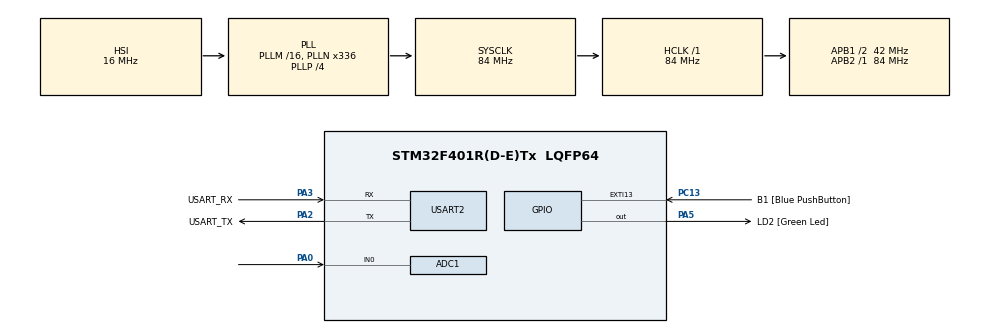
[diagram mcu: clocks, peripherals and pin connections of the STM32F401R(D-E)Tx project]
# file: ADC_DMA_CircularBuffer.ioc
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Mcu.Family=STM32F4
PC15-OSC32_OUT.Mode=LSE-External-Oscillator
PA2.GPIO_PuPd=GPIO_NOPULL
Dma.ADC1.0.Instance=DMA2_Stream0
RCC.CortexFreq_Value=84000000
ADC1.Rank-0\#ChannelRegularConversion=1
PC13-ANTI_TAMP.GPIO_PuPd=GPIO_NOPULL
ADC1.ContinuousConvMode=ENABLE
PC13-ANTI_TAMP.GPIO_Label=B1 [Blue PushButton]
PA14.GPIO_Label=TCK
PA3.GPIO_PuPd=GPIO_NOPULL
PH1\ -\ OSC_OUT.Mode=HSE-External-Clock-Source
PA2.GPIO_Speed=GPIO_SPEED_FREQ_LOW
RCC.APB1CLKDivider=RCC_HCLK_DIV2
PC14-OSC32_IN.Signal=RCC_OSC32_IN
PA3.GPIO_Speed=GPIO_SPEED_FREQ_LOW
RCC.SYSCLKSource=RCC_SYSCLKSOURCE_PLLCLK
ProjectManager.StackSize=0x400
PA0-WKUP.Signal=ADCx_IN0
PA3.Mode=Asynchronous
PA13.Signal=SYS_JTMS-SWDIO
Dma.ADC1.0.PeriphDataAlignment=DMA_PDATAALIGN_HALFWORD
PH0\ -\ OSC_IN.Mode=HSE-External-Clock-Source
PH0\ -\ OSC_IN.Signal=RCC_OSC_IN
ProjectManager.TargetToolchain=Other Toolchains (GPDSC)
Dma.ADC1.0.Mode=DMA_CIRCULAR
PA3.GPIO_Mode=GPIO_MODE_AF_PP
RCC.HCLKFreq_Value=84000000
Dma.ADC1.0.Priority=DMA_PRIORITY_LOW
RCC.APB2TimFreq_Value=84000000
Dma.ADC1.0.Direction=DMA_PERIPH_TO_MEMORY
NVIC.DMA2_Stream0_IRQn=true\:0\:0\:false\:false\:true\:false\:true
PC15-OSC32_OUT.Signal=RCC_OSC32_OUT
Dma.ADC1.0.MemDataAlignment=DMA_MDATAALIGN_HALFWORD
RCC.AHBFreq_Value=84000000
PA5.Signal=GPIO_Output
ADC1.Channel-0\#ChannelRegularConversion=ADC_CHANNEL_0
RCC.HSE_VALUE=8000000
PH1\ -\ OSC_OUT.Signal=RCC_OSC_OUT
board=NUCLEO-F401RE
PC13-ANTI_TAMP.Signal=GPXTI13
RCC.VCOOutputFreq_Value=336000000
RCC.APB2Freq_Value=84000000
PC14-OSC32_IN.Mode=LSE-External-Oscillator
PA14.Mode=Serial_Wire
PA5.GPIO_PuPd=GPIO_NOPULL
Dma.ADC1.0.PeriphInc=DMA_PINC_DISABLE
SH.ADCx_IN0.0=ADC1_IN0,IN0
ADC1.DMAContinuousRequests=ENABLE
PA13.Mode=Serial_Wire
Mcu.Name=STM32F401R(D-E)Tx
ADC1.SamplingTime-0\#ChannelRegularConversion=ADC_SAMPLETIME_3CYCLES
PA2.Signal=USART2_TX
PA13.GPIO_Label=TMS
RCC.48MHZClocksFreq_Value=48000000
PB3.Signal=SYS_JTDO-SWO
RCC.SYSCLKFreq_VALUE=84000000
Mcu.Package=LQFP64
ADC1.master=1
PA5.GPIO_Label=LD2 [Green Led]
USART2.VirtualMode=VM_ASYNC
PC13-ANTI_TAMP.GPIO_ModeDefaultEXTI=GPIO_MODE_IT_FALLING
PA2.GPIO_Label=USART_TX
PA14.Signal=SYS_JTCK-SWCLK
Dma.ADC1.0.MemInc=DMA_MINC_ENABLE
ProjectManager.HeapSize=0x200
RCC.HSI_VALUE=16000000
RCC.PLLP=RCC_PLLP_DIV4
PA5.GPIO_Speed=GPIO_SPEED_FREQ_LOW
RCC.PLLQ=7
NVIC.PriorityGroup=NVIC_PRIORITYGROUP_0
ADC1.NbrOfConversionFlag=1
RCC.PLLN=336
RCC.APB1TimFreq_Value=84000000
PA2.Mode=Asynchronous
Dma.ADC1.0.FIFOMode=DMA_FIFOMODE_DISABLE
Dma.Request0=ADC1
RCC.APB1Freq_Value=42000000
PA5.GPIO_Mode=GPIO_MODE_OUTPUT_PP
PA3.GPIO_Label=USART_RX
PA3.Signal=USART2_RX
PA2.GPIO_Mode=GPIO_MODE_AF_PP
PB3.GPIO_Label=SWO

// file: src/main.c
/* USER CODE BEGIN Header */
/**
  ******************************************************************************
  * @file           : main.c
  * @brief          : Main program body
  ******************************************************************************
  * @attention
  *
  * <h2><center>&copy; Copyright (c) 2021 STMicroelectronics.
  * All rights reserved.</center></h2>
  *
  * This software component is licensed by ST under BSD 3-Clause license,
  * the "License"; You may not use this file except in compliance with the
  * License. You may obtain a copy of the License at:
  *                        opensource.org/licenses/BSD-3-Clause
  *
  ******************************************************************************
  */
/* USER CODE END Header */
#include "main.h"

ADC_HandleTypeDef hadc1;
DMA_HandleTypeDef hdma_adc1;

UART_HandleTypeDef huart2;

/* USER CODE BEGIN PV */
uint16_t adc_data[16];
/* USER CODE END PV */

void SystemClock_Config(void);
static void MX_GPIO_Init(void);
static void MX_DMA_Init(void);
static void MX_ADC1_Init(void);
static void MX_USART2_UART_Init(void);

/* USER CODE BEGIN 0 */
void HAL_ADC_ConvCpltCallback(ADC_HandleTypeDef* hadc)
{
  __NOP();
}
/* USER CODE END 0 */

int main(void)
{

  /* MCU Configuration--------------------------------------------------------*/

  /* Reset of all peripherals, Initializes the Flash interface and the Systick. */
  HAL_Init();

  /* Configure the system clock */
  SystemClock_Config();

  /* Initialize all configured peripherals */
  MX_GPIO_Init();
  MX_DMA_Init();
  MX_ADC1_Init();
  MX_USART2_UART_Init();

  /* USER CODE BEGIN 2 */
  HAL_ADC_Start_DMA(&hadc1, (uint32_t*)adc_data, 16);
  /* USER CODE END 2 */

  /* Infinite loop */
  while (1)
  {

  }
}

void SystemClock_Config(void)
{
  RCC_OscInitTypeDef RCC_OscInitStruct = {0};
  RCC_ClkInitTypeDef RCC_ClkInitStruct = {0};

  /** Configure the main internal regulator output voltage
  */
  __HAL_RCC_PWR_CLK_ENABLE();
  __HAL_PWR_VOLTAGESCALING_CONFIG(PWR_REGULATOR_VOLTAGE_SCALE2);
  /** Initializes the RCC Oscillators according to the specified parameters
  * in the RCC_OscInitTypeDef structure.
  */
  RCC_OscInitStruct.OscillatorType = RCC_OSCILLATORTYPE_HSI;
  RCC_OscInitStruct.HSIState = RCC_HSI_ON;
  RCC_OscInitStruct.HSICalibrationValue = RCC_HSICALIBRATION_DEFAULT;
  RCC_OscInitStruct.PLL.PLLState = RCC_PLL_ON;
  RCC_OscInitStruct.PLL.PLLSource = RCC_PLLSOURCE_HSI;
  RCC_OscInitStruct.PLL.PLLM = 16;
  RCC_OscInitStruct.PLL.PLLN = 336;
  RCC_OscInitStruct.PLL.PLLP = RCC_PLLP_DIV4;
  RCC_OscInitStruct.PLL.PLLQ = 7;
  if (HAL_RCC_OscConfig(&RCC_OscInitStruct) != HAL_OK)
  {
    Error_Handler();
  }
  /** Initializes the CPU, AHB and APB buses clocks
  */
  RCC_ClkInitStruct.ClockType = RCC_CLOCKTYPE_HCLK|RCC_CLOCKTYPE_SYSCLK
                              |RCC_CLOCKTYPE_PCLK1|RCC_CLOCKTYPE_PCLK2;
  RCC_ClkInitStruct.SYSCLKSource = RCC_SYSCLKSOURCE_PLLCLK;
  RCC_ClkInitStruct.AHBCLKDivider = RCC_SYSCLK_DIV1;
  RCC_ClkInitStruct.APB1CLKDivider = RCC_HCLK_DIV2;
  RCC_ClkInitStruct.APB2CLKDivider = RCC_HCLK_DIV1;

  if (HAL_RCC_ClockConfig(&RCC_ClkInitStruct, FLASH_LATENCY_2) != HAL_OK)
  {
    Error_Handler();
  }
}

static void MX_ADC1_Init(void)
{

  ADC_ChannelConfTypeDef sConfig = {0};

  /** Configure the global features of the ADC (Clock, Resolution, Data Alignment and number of conversion)
  */
  hadc1.Instance = ADC1;
  hadc1.Init.ClockPrescaler = ADC_CLOCK_SYNC_PCLK_DIV4;
  hadc1.Init.Resolution = ADC_RESOLUTION_12B;
  hadc1.Init.ScanConvMode = DISABLE;
  hadc1.Init.ContinuousConvMode = ENABLE;
  hadc1.Init.DiscontinuousConvMode = DISABLE;
  hadc1.Init.ExternalTrigConvEdge = ADC_EXTERNALTRIGCONVEDGE_NONE;
  hadc1.Init.ExternalTrigConv = ADC_SOFTWARE_START;
  hadc1.Init.DataAlign = ADC_DATAALIGN_RIGHT;
  hadc1.Init.NbrOfConversion = 1;
  hadc1.Init.DMAContinuousRequests = ENABLE;
  hadc1.Init.EOCSelection = ADC_EOC_SINGLE_CONV;

  if (HAL_ADC_Init(&hadc1) != HAL_OK)
  {
    Error_Handler();
  }
  /** Configure for the selected ADC regular channel its corresponding rank in the sequencer and its sample time.
  */
  sConfig.Channel = ADC_CHANNEL_0;
  sConfig.Rank = 1;
  sConfig.SamplingTime = ADC_SAMPLETIME_3CYCLES;
  if (HAL_ADC_ConfigChannel(&hadc1, &sConfig) != HAL_OK)
  {
    Error_Handler();
  }

}

static void MX_USART2_UART_Init(void)
{

  huart2.Instance = USART2;
  huart2.Init.BaudRate = 115200;
  huart2.Init.WordLength = UART_WORDLENGTH_8B;
  huart2.Init.StopBits = UART_STOPBITS_1;
  huart2.Init.Parity = UART_PARITY_NONE;
  huart2.Init.Mode = UART_MODE_TX_RX;
  huart2.Init.HwFlowCtl = UART_HWCONTROL_NONE;
  huart2.Init.OverSampling = UART_OVERSAMPLING_16;
  if (HAL_UART_Init(&huart2) != HAL_OK)
  {
    Error_Handler();
  }

}

static void MX_DMA_Init(void)
{

  /* DMA controller clock enable */
  __HAL_RCC_DMA2_CLK_ENABLE();

  /* DMA interrupt init */
  /* DMA2_Stream0_IRQn interrupt configuration */
  HAL_NVIC_SetPriority(DMA2_Stream0_IRQn, 0, 0);
  HAL_NVIC_EnableIRQ(DMA2_Stream0_IRQn);

}

static void MX_GPIO_Init(void)
{
  GPIO_InitTypeDef GPIO_InitStruct = {0};

  /* GPIO Ports Clock Enable */
  __HAL_RCC_GPIOC_CLK_ENABLE();
  __HAL_RCC_GPIOH_CLK_ENABLE();
  __HAL_RCC_GPIOA_CLK_ENABLE();
  __HAL_RCC_GPIOB_CLK_ENABLE();

  /*Configure GPIO pin Output Level */
  HAL_GPIO_WritePin(LD2_GPIO_Port, LD2_Pin, GPIO_PIN_RESET);

  /*Configure GPIO pin : B1_Pin */
  GPIO_InitStruct.Pin = B1_Pin;
  GPIO_InitStruct.Mode = GPIO_MODE_IT_FALLING;
  GPIO_InitStruct.Pull = GPIO_NOPULL;
  HAL_GPIO_Init(B1_GPIO_Port, &GPIO_InitStruct);

  /*Configure GPIO pin : LD2_Pin */
  GPIO_InitStruct.Pin = LD2_Pin;
  GPIO_InitStruct.Mode = GPIO_MODE_OUTPUT_PP;
  GPIO_InitStruct.Pull = GPIO_NOPULL;
  GPIO_InitStruct.Speed = GPIO_SPEED_FREQ_LOW;
  HAL_GPIO_Init(LD2_GPIO_Port, &GPIO_InitStruct);

}

void Error_Handler(void)
{
  __disable_irq();
  while (1)
  {
  }
}

/************************ (C) COPYRIGHT STMicroelectronics *****END OF FILE****/
